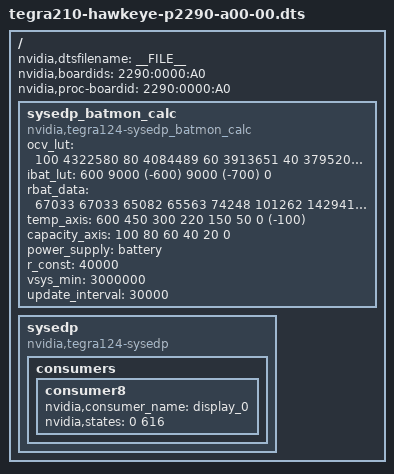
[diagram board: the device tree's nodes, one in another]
/*
 * tegra210-hawkeye-p2290-a00-00.dts: Hawkeye P2290 A00 board.
 *
 * Copyright (c) 2014-2015, NVIDIA CORPORATION.  All rights reserved.
 *
 * This program is free software; you can redistribute it and/or modify
 * it under the terms of the GNU General Public License as published by
 * the Free Software Foundation; version 2 of the License.
 *
 * This program is distributed in the hope that it will be useful, but WITHOUT
 * ANY WARRANTY; without even the implied warranty of MERCHANTABILITY or
 * FITNESS FOR A PARTICULAR PURPOSE.  See the GNU General Public License for
 * more details.
 */

#include "tegra210-hawkeye-p2290-common.dtsi"

/ {
	nvidia,dtsfilename = __FILE__;
	nvidia,boardids = "2290:0000:A0";
	nvidia,proc-boardid = "2290:0000:A0";

	sysedp_batmon_calc {
		/* non-shipping ST8 battery */
		compatible = "nvidia,tegra124-sysedp_batmon_calc";
		ocv_lut = <
			100 4322580
			80  4084489
			60  3913651
			40  3795200
			20  3700276
			0   3500000
		>;
		ibat_lut = <
			600    9000
			(-600) 9000
			(-700) 0
		>;
		rbat_data = <
		/*	600	450	300	220	150	50	0	-100   deci Celsius */
			67033	67033	65082	65563	74248	101262	142941	142941	/* 100% SOC */
			67004	67004	65118	64381	73787	100638	142065	142065	/* 80% SOC  */
			67103	67103	65371	64000	70778	90388	114825	114825	/* 60% SOC  */
			67408	67408	65894	64533	70229	87182	104433	104433 	/* 40% SOC  */
			68272	68272	67117	65945	71666	89842	108942	108942	/* 20% SOC  */
			72328	72328	71869	71538	81803	95724	118174	118174	/* 0% SOC   */
		>;
		temp_axis = <600 450 300 220 150 50 0 (-100)>;
		capacity_axis = <100 80 60 40 20 0>;
		power_supply = "battery";
		r_const = <40000>;
		vsys_min = <3000000>;
		update_interval = <30000>;
	};

	sysedp {
		compatible = "nvidia,tegra124-sysedp";
		consumers {
			consumer8 {
				/* non-shipping ST8 AUO 8" display */
				nvidia,consumer_name = "display_0";
				nvidia,states = <0 616>;
			};
		};
	};
};
